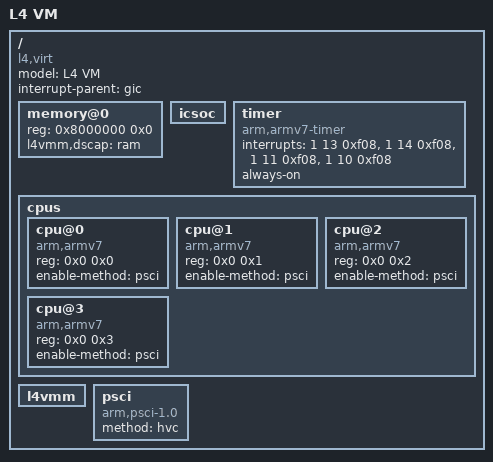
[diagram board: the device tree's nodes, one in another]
/*
 * Device tree for a virtual machine without any hardware pass-through.
 */

/dts-v1/;
/include/ "skeleton.dtsi"
/include/ "vmm-devices-arm.dtsi"
/include/ "ic-arm.dtsi"

/ {
    model = "L4 VM";
    compatible = "l4,virt", "linux,dummy-virt";

    interrupt-parent = <&gic>;

    memory@0 {
        device_type = "memory";
        // Ram starts at 128MB
        // Size will be updated by uvmm based on ds size
        reg = <0x8000000 0x0>;
        l4vmm,dscap = "ram";
    };

    icsoc {
        ranges = <0x0 0x40000 0x3000>;
    };

    timer {
      compatible = "arm,armv7-timer";
      interrupts = <1 13 0xf08>,
                   <1 14 0xf08>,
                   <1 11 0xf08>,
                   <1 10 0xf08>;
      always-on;
    };

    cpus {
      #address-cells = <2>;
      #size-cells = <0>;

      cpu@0 {
        device_type = "cpu";
        compatible = "arm,armv7";
        reg = <0x0 0x0>;
        enable-method = "psci";
      };

      cpu@1 {
        device_type = "cpu";
        compatible = "arm,armv7";
        reg = <0x0 0x1>;
        enable-method = "psci";
      };

      cpu@2 {
        device_type = "cpu";
        compatible = "arm,armv7";
        reg = <0x0 0x2>;
        enable-method = "psci";
      };

      cpu@3 {
        device_type = "cpu";
        compatible = "arm,armv7";
        reg = <0x0 0x3>;
        enable-method = "psci";
      };
    };

    l4vmm {
        ranges = <0x0 0x10000 0x21000>;
    };

    psci {
        compatible = "arm,psci-1.0";
        method = "hvc";
    };
};
